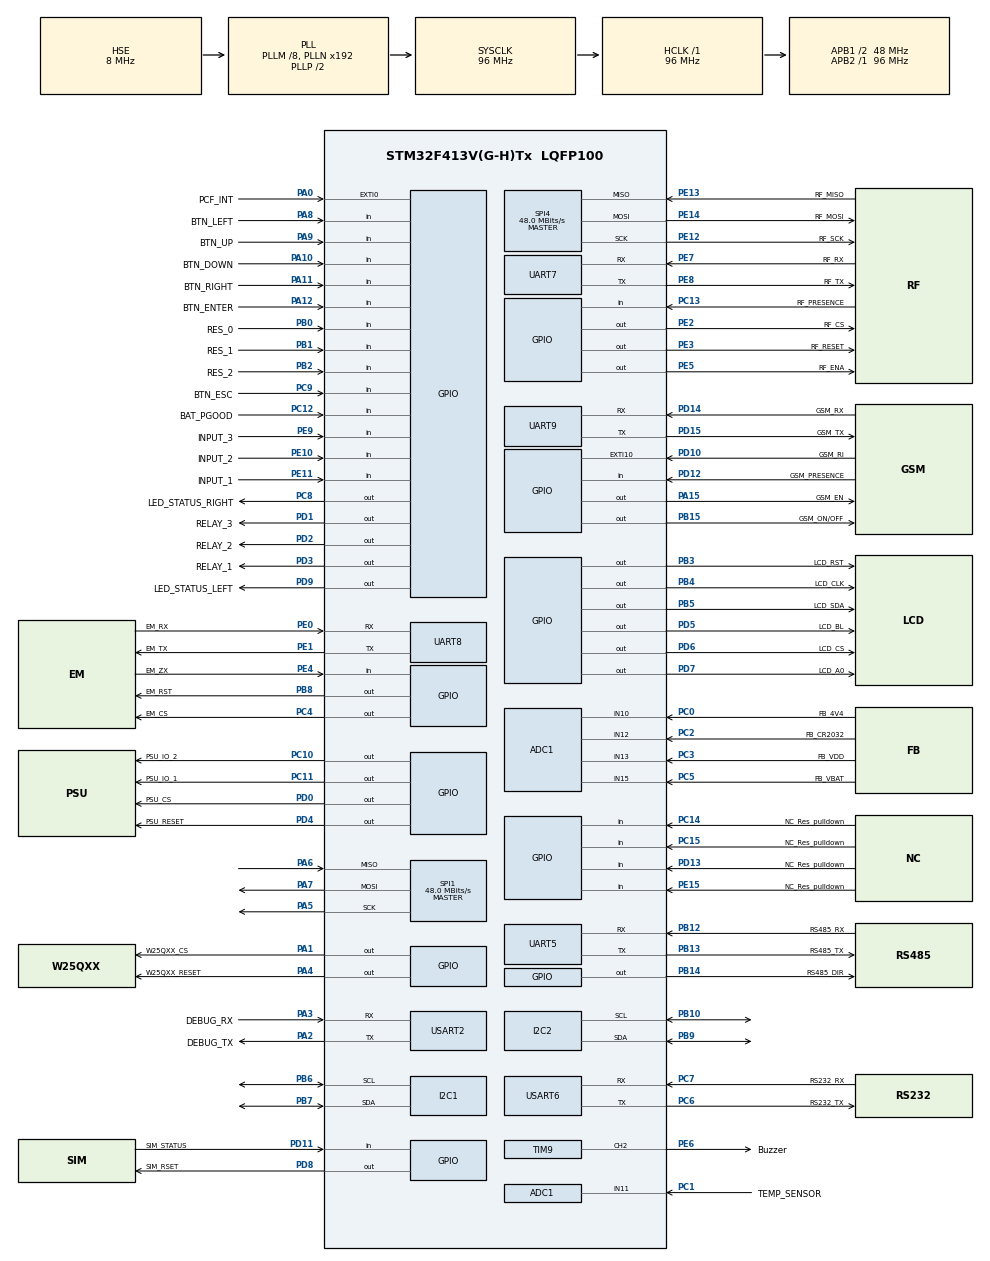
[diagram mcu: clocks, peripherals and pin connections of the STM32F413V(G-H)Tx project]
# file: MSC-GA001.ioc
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ADC1.Channel-0\#ChannelRegularConversion=ADC_CHANNEL_10
ADC1.NbrOfConversionFlag=1
ADC1.Rank-0\#ChannelRegularConversion=1
ADC1.SamplingTime-0\#ChannelRegularConversion=ADC_SAMPLETIME_3CYCLES
ADC1.master=1
Mcu.Family=STM32F4
Mcu.Name=STM32F413V(G-H)Tx
Mcu.Package=LQFP100
NVIC.PriorityGroup=NVIC_PRIORITYGROUP_4
NVIC.TIM1_BRK_TIM9_IRQn=true\:0\:0\:false\:false\:true\:true\:true
PA0.GPIO_Label=PCF_INT
PA0.GPIO_PuPd=GPIO_PULLUP
PA0.Signal=GPXTI0
PA1.GPIO_Label=W25QXX_CS
PA1.Signal=GPIO_Output
PA10.GPIO_Label=BTN_DOWN
PA10.GPIO_PuPd=GPIO_PULLUP
PA10.Signal=GPIO_Input
PA11.GPIO_Label=BTN_RIGHT
PA11.GPIO_PuPd=GPIO_PULLUP
PA11.Signal=GPIO_Input
PA12.GPIO_Label=BTN_ENTER
PA12.GPIO_PuPd=GPIO_PULLUP
PA12.Signal=GPIO_Input
PA13.Mode=Serial_Wire
PA13.Signal=SYS_JTMS-SWDIO
PA14.Mode=Serial_Wire
PA14.Signal=SYS_JTCK-SWCLK
PA15.GPIO_Label=GSM_EN
PA15.GPIO_PuPd=GPIO_PULLUP
PA15.Signal=GPIO_Output
PA2.GPIO_Label=DEBUG_TX
PA2.Mode=Asynchronous
PA2.Signal=USART2_TX
PA3.GPIO_Label=DEBUG_RX
PA3.Mode=Asynchronous
PA3.Signal=USART2_RX
PA4.GPIO_Label=W25QXX_RESET
PA4.Signal=GPIO_Output
PA5.Mode=Full_Duplex_Master
PA5.Signal=SPI1_SCK
PA6.Mode=Full_Duplex_Master
PA6.Signal=SPI1_MISO
PA7.Mode=Full_Duplex_Master
PA7.Signal=SPI1_MOSI
PA8.GPIO_Label=BTN_LEFT
PA8.GPIO_PuPd=GPIO_PULLUP
PA8.Signal=GPIO_Input
PA9.GPIO_Label=BTN_UP
PA9.GPIO_PuPd=GPIO_PULLUP
PA9.Signal=GPIO_Input
PB0.GPIO_Label=RES_0
PB0.GPIO_PuPd=GPIO_PULLUP
PB0.Signal=GPIO_Input
PB1.GPIO_Label=RES_1
PB1.GPIO_PuPd=GPIO_PULLUP
PB1.Signal=GPIO_Input
PB10.Mode=I2C
PB10.Signal=I2C2_SCL
PB12.GPIO_Label=RS485_RX
PB12.Mode=Asynchronous
PB12.Signal=UART5_RX
PB13.GPIO_Label=RS485_TX
PB13.Mode=Asynchronous
PB13.Signal=UART5_TX
PB14.GPIO_Label=RS485_DIR
PB14.Signal=GPIO_Output
PB15.GPIO_Label=GSM_ON/OFF
PB15.Signal=GPIO_Output
PB2.GPIO_Label=RES_2
PB2.GPIO_PuPd=GPIO_PULLUP
PB2.Signal=GPIO_Input
PB3.GPIO_Label=LCD_RST
PB3.Signal=GPIO_Output
PB4.GPIO_Label=LCD_CLK
PB4.Signal=GPIO_Output
PB5.GPIO_Label=LCD_SDA
PB5.Signal=GPIO_Output
PB6.Mode=I2C
PB6.Signal=I2C1_SCL
PB7.Mode=I2C
PB7.Signal=I2C1_SDA
PB8.GPIO_Label=EM_RST
PB8.Signal=GPIO_Output
PB9.Mode=I2C
PB9.Signal=I2C2_SDA
PC0.GPIO_Label=FB_4V4
PC0.Signal=ADCx_IN10
PC1.GPIO_Label=TEMP_SENSOR
PC1.Signal=ADCx_IN11
PC10.GPIO_Label=PSU_IO_2
PC10.Signal=GPIO_Output
PC11.GPIO_Label=PSU_IO_1
PC11.Signal=GPIO_Output
PC12.GPIO_Label=BAT_PGOOD
PC12.GPIO_PuPd=GPIO_PULLUP
PC12.Signal=GPIO_Input
PC13.GPIO_Label=RF_PRESENCE
PC13.GPIO_PuPd=GPIO_PULLUP
PC13.Signal=GPIO_Input
PC14-OSC32_IN.GPIO_Label=NC_Res_pulldown
PC14-OSC32_IN.GPIO_PuPd=GPIO_PULLDOWN
PC14-OSC32_IN.Signal=GPIO_Input
PC15-OSC32_OUT.GPIO_Label=NC_Res_pulldown
PC15-OSC32_OUT.GPIO_PuPd=GPIO_PULLDOWN
PC15-OSC32_OUT.Signal=GPIO_Input
PC2.GPIO_Label=FB_CR2032
PC2.Signal=ADCx_IN12
PC3.GPIO_Label=FB_VDD
PC3.Signal=ADCx_IN13
PC4.GPIO_Label=EM_CS
PC4.Signal=GPIO_Output
PC5.GPIO_Label=FB_VBAT
PC5.Signal=ADCx_IN15
PC6.GPIO_Label=RS232_TX
PC6.Mode=Asynchronous
PC6.Signal=USART6_TX
PC7.GPIO_Label=RS232_RX
PC7.Mode=Asynchronous
PC7.Signal=USART6_RX
PC8.GPIO_Label=LED_STATUS_RIGHT
PC8.Signal=GPIO_Output
PC9.GPIO_Label=BTN_ESC
PC9.GPIO_PuPd=GPIO_PULLUP
PC9.Signal=GPIO_Input
PD0.GPIO_Label=PSU_CS
PD0.Signal=GPIO_Output
PD1.GPIO_Label=RELAY_3
PD1.Signal=GPIO_Output
PD10.GPIO_Label=GSM_RI
PD10.GPIO_PuPd=GPIO_PULLUP
PD10.Signal=GPXTI10
PD11.GPIO_Label=SIM_STATUS
PD11.GPIO_PuPd=GPIO_PULLUP
PD11.Signal=GPIO_Input
PD12.GPIO_Label=GSM_PRESENCE
PD12.GPIO_PuPd=GPIO_PULLUP
PD12.Signal=GPIO_Input
PD13.GPIO_Label=NC_Res_pulldown
PD13.GPIO_PuPd=GPIO_PULLDOWN
PD13.Signal=GPIO_Input
PD14.GPIO_Label=GSM_RX
PD14.Mode=Asynchronous
PD14.Signal=UART9_RX
PD15.GPIO_Label=GSM_TX
PD15.Mode=Asynchronous
PD15.Signal=UART9_TX
PD2.GPIO_Label=RELAY_2
PD2.Signal=GPIO_Output
PD3.GPIO_Label=RELAY_1
PD3.Signal=GPIO_Output
PD4.GPIO_Label=PSU_RESET
PD4.Signal=GPIO_Output
PD5.GPIO_Label=LCD_BL
PD5.Signal=GPIO_Output
PD6.GPIO_Label=LCD_CS
PD6.Signal=GPIO_Output
PD7.GPIO_Label=LCD_A0
PD7.Signal=GPIO_Output
PD8.GPIO_Label=SIM_RSET
PD8.Signal=GPIO_Output
PD9.GPIO_Label=LED_STATUS_LEFT
PD9.Signal=GPIO_Output
PE0.GPIO_Label=EM_RX
PE0.Mode=Asynchronous
PE0.Signal=UART8_RX
PE1.GPIO_Label=EM_TX
PE1.Mode=Asynchronous
PE1.Signal=UART8_TX
PE10.GPIO_Label=INPUT_2
PE10.GPIO_PuPd=GPIO_PULLUP
PE10.Signal=GPIO_Input
PE11.GPIO_Label=INPUT_1
PE11.GPIO_PuPd=GPIO_PULLUP
PE11.Signal=GPIO_Input
PE12.GPIO_Label=RF_SCK
PE12.Mode=Full_Duplex_Master
PE12.Signal=SPI4_SCK
PE13.GPIO_Label=RF_MISO
PE13.Mode=Full_Duplex_Master
PE13.Signal=SPI4_MISO
PE14.GPIO_Label=RF_MOSI
PE14.Mode=Full_Duplex_Master
PE14.Signal=SPI4_MOSI
PE15.GPIO_Label=NC_Res_pulldown
PE15.GPIO_PuPd=GPIO_PULLDOWN
PE15.Signal=GPIO_Input
PE2.GPIO_Label=RF_CS
PE2.Signal=GPIO_Output
PE3.GPIO_Label=RF_RESET
PE3.Signal=GPIO_Output
PE4.GPIO_Label=EM_ZX
PE4.GPIO_PuPd=GPIO_PULLUP
PE4.Signal=GPIO_Input
PE5.GPIO_Label=RF_ENA
PE5.Signal=GPIO_Output
PE6.GPIO_Label=Buzzer
PE6.Signal=S_TIM9_CH2
PE7.GPIO_Label=RF_RX
PE7.Mode=Asynchronous
PE7.Signal=UART7_RX
PE8.GPIO_Label=RF_TX
PE8.Mode=Asynchronous
PE8.Signal=UART7_TX
PE9.GPIO_Label=INPUT_3
PE9.GPIO_PuPd=GPIO_PULLUP
PE9.Signal=GPIO_Input
PH0\ -\ OSC_IN.Mode=HSE-External-Oscillator
PH0\ -\ OSC_IN.Signal=RCC_OSC_IN
PH1\ -\ OSC_OUT.Mode=HSE-External-Oscillator
PH1\ -\ OSC_OUT.Signal=RCC_OSC_OUT
ProjectManager.HeapSize=0x200
ProjectManager.StackSize=0x400
ProjectManager.TargetToolchain=STM32CubeIDE
RCC.AHBFreq_Value=96000000
RCC.APB1CLKDivider=RCC_HCLK_DIV2
RCC.APB1Freq_Value=48000000
RCC.APB1TimFreq_Value=96000000
RCC.APB2Freq_Value=96000000
RCC.APB2TimFreq_Value=96000000
RCC.CortexFreq_Value=96000000
RCC.EnbaleCSS=true
RCC.HCLKFreq_Value=96000000
RCC.HSE_VALUE=8000000
RCC.PLLM=8
RCC.PLLSourceVirtual=RCC_PLLSOURCE_HSE
RCC.SYSCLKFreq_VALUE=96000000
RCC.SYSCLKSource=RCC_SYSCLKSOURCE_PLLCLK
RCC.USBFreq_Value=96000000
RCC.VCOOutputFreq_Value=192000000
SH.ADCx_IN10.0=ADC1_IN10,IN10
SH.ADCx_IN11.0=ADC1_IN11,IN11
SH.ADCx_IN12.0=ADC1_IN12,IN12
SH.ADCx_IN13.0=ADC1_IN13,IN13
SH.ADCx_IN15.0=ADC1_IN15,IN15
SH.S_TIM9_CH2.0=TIM9_CH2,PWM Generation2 CH2
SPI1.CalculateBaudRate=48.0 MBits/s
SPI1.Direction=SPI_DIRECTION_2LINES
SPI1.Mode=SPI_MODE_MASTER
SPI1.VirtualType=VM_MASTER
SPI4.CalculateBaudRate=48.0 MBits/s
SPI4.Direction=SPI_DIRECTION_2LINES
SPI4.Mode=SPI_MODE_MASTER
SPI4.VirtualType=VM_MASTER
TIM9.AutoReloadPreload=TIM_AUTORELOAD_PRELOAD_ENABLE
TIM9.Channel-PWM\ Generation2\ CH2=TIM_CHANNEL_2
TIM9.Period=1000-1
TIM9.Prescaler=24-1
TIM9.Pulse-PWM\ Generation2\ CH2=0
UART5.VirtualMode=Asynchronous
UART7.VirtualMode=Asynchronous
UART8.VirtualMode=Asynchronous
UART9.VirtualMode=Asynchronous
USART2.VirtualMode=VM_ASYNC
USART6.VirtualMode=VM_ASYNC
board=custom

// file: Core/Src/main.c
/* USER CODE BEGIN Header */
/**
  ******************************************************************************
  * @file           : main.c
  * @brief          : Main program body
  ******************************************************************************
  * @attention
  *
  * <h2><center>&copy; Copyright (c) 2021 STMicroelectronics.
  * All rights reserved.</center></h2>
  *
  * This software component is licensed by ST under BSD 3-Clause license,
  * the "License"; You may not use this file except in compliance with the
  * License. You may obtain a copy of the License at:
  *                        opensource.org/licenses/BSD-3-Clause
  *
  ******************************************************************************
  */
/* USER CODE END Header */
#include "main.h"

/* USER CODE BEGIN Includes */
#include "../apps/resource.h"
/* USER CODE END Includes */

ADC_HandleTypeDef hadc1;

I2C_HandleTypeDef hi2c1;
I2C_HandleTypeDef hi2c2;

SPI_HandleTypeDef hspi1;
SPI_HandleTypeDef hspi4;

TIM_HandleTypeDef htim9;

UART_HandleTypeDef huart5;
UART_HandleTypeDef huart7;
UART_HandleTypeDef huart8;
UART_HandleTypeDef huart9;
UART_HandleTypeDef huart2;
UART_HandleTypeDef huart6;

void SystemClock_Config(void);
static void MX_GPIO_Init(void);
static void MX_ADC1_Init(void);
static void MX_I2C1_Init(void);
static void MX_I2C2_Init(void);
static void MX_SPI1_Init(void);
static void MX_SPI4_Init(void);
static void MX_UART5_Init(void);
static void MX_UART7_Init(void);
static void MX_UART8_Init(void);
static void MX_UART9_Init(void);
static void MX_USART2_UART_Init(void);
static void MX_USART6_UART_Init(void);
static void MX_TIM9_Init(void);

int main(void)
{

  /* MCU Configuration--------------------------------------------------------*/

  /* Reset of all peripherals, Initializes the Flash interface and the Systick. */
  HAL_Init();

  /* Configure the system clock */
  SystemClock_Config();

  /* Initialize all configured peripherals */
  MX_GPIO_Init();
  MX_ADC1_Init();
  MX_I2C1_Init();
  MX_I2C2_Init();
  MX_SPI1_Init();
  MX_SPI4_Init();
  MX_UART5_Init();
  MX_UART7_Init();
  MX_UART8_Init();
  MX_UART9_Init();
  MX_USART2_UART_Init();
  MX_USART6_UART_Init();
  MX_TIM9_Init();
  /* USER CODE BEGIN 2 */
  /*start timer 9 for PWM out for the buzzer*/
  HAL_TIM_Base_Start_IT(&htim9);
  /* Enable the main output */
  HAL_TIM_PWM_Start(&htim9, TIM_CHANNEL_2);//Buzzer
  /*Update the duty cycle based on the period setting from QMX ==>1000 is 4kHz frequency,
   and 50% duty cycle*/
  htim9.Init.Period = 1000-1;
  htim9.Instance->CCR1 = (unsigned short) ((uint32_t) (Duty_Percent*htim9.Init.Period/100));

  /* USER CODE END 2 */

  /* Infinite loop */
  /* USER CODE BEGIN WHILE */
  while (1)
  {
	  //update all timers
	  DoTimers();
	  //update all switches
	  UpdateAllSwitches();
	  /*Update all the LED data from the buffer*/
	  UpdateLEDoutputs(&RawLEDdata);
	  //Toggle LED to test the loop continuing
	  ToggleLEDstate(&RawLEDdata,LED_STATUS_RIGHT);
	  //Run main app
	  doApplication();
	  //LCD display driver
	  doDisplay();
	  /*Buzzer driver*/
	  doBeepControl();
	  /*Update the buzzer out put*/
	  DoPWM_Buzzer(htim9, Duty_Percent);
    /* USER CODE END WHILE */

  }
}

void SystemClock_Config(void)
{
  RCC_OscInitTypeDef RCC_OscInitStruct = {0};
  RCC_ClkInitTypeDef RCC_ClkInitStruct = {0};

  /** Configure the main internal regulator output voltage
  */
  __HAL_RCC_PWR_CLK_ENABLE();
  __HAL_PWR_VOLTAGESCALING_CONFIG(PWR_REGULATOR_VOLTAGE_SCALE1);
  /** Initializes the RCC Oscillators according to the specified parameters
  * in the RCC_OscInitTypeDef structure.
  */
  RCC_OscInitStruct.OscillatorType = RCC_OSCILLATORTYPE_HSE;
  RCC_OscInitStruct.HSEState = RCC_HSE_ON;
  RCC_OscInitStruct.PLL.PLLState = RCC_PLL_ON;
  RCC_OscInitStruct.PLL.PLLSource = RCC_PLLSOURCE_HSE;
  RCC_OscInitStruct.PLL.PLLM = 8;
  RCC_OscInitStruct.PLL.PLLN = 192;
  RCC_OscInitStruct.PLL.PLLP = RCC_PLLP_DIV2;
  RCC_OscInitStruct.PLL.PLLQ = 2;
  RCC_OscInitStruct.PLL.PLLR = 2;
  if (HAL_RCC_OscConfig(&RCC_OscInitStruct) != HAL_OK)
  {
    Error_Handler();
  }
  /** Initializes the CPU, AHB and APB buses clocks
  */
  RCC_ClkInitStruct.ClockType = RCC_CLOCKTYPE_HCLK|RCC_CLOCKTYPE_SYSCLK
                              |RCC_CLOCKTYPE_PCLK1|RCC_CLOCKTYPE_PCLK2;
  RCC_ClkInitStruct.SYSCLKSource = RCC_SYSCLKSOURCE_PLLCLK;
  RCC_ClkInitStruct.AHBCLKDivider = RCC_SYSCLK_DIV1;
  RCC_ClkInitStruct.APB1CLKDivider = RCC_HCLK_DIV2;
  RCC_ClkInitStruct.APB2CLKDivider = RCC_HCLK_DIV1;

  if (HAL_RCC_ClockConfig(&RCC_ClkInitStruct, FLASH_LATENCY_3) != HAL_OK)
  {
    Error_Handler();
  }
  /** Enables the Clock Security System
  */
  HAL_RCC_EnableCSS();
}

static void MX_ADC1_Init(void)
{

  ADC_ChannelConfTypeDef sConfig = {0};

  /** Configure the global features of the ADC (Clock, Resolution, Data Alignment and number of conversion)
  */
  hadc1.Instance = ADC1;
  hadc1.Init.ClockPrescaler = ADC_CLOCK_SYNC_PCLK_DIV4;
  hadc1.Init.Resolution = ADC_RESOLUTION_12B;
  hadc1.Init.ScanConvMode = DISABLE;
  hadc1.Init.ContinuousConvMode = DISABLE;
  hadc1.Init.DiscontinuousConvMode = DISABLE;
  hadc1.Init.ExternalTrigConvEdge = ADC_EXTERNALTRIGCONVEDGE_NONE;
  hadc1.Init.ExternalTrigConv = ADC_SOFTWARE_START;
  hadc1.Init.DataAlign = ADC_DATAALIGN_RIGHT;
  hadc1.Init.NbrOfConversion = 1;
  hadc1.Init.DMAContinuousRequests = DISABLE;
  hadc1.Init.EOCSelection = ADC_EOC_SINGLE_CONV;
  if (HAL_ADC_Init(&hadc1) != HAL_OK)
  {
    Error_Handler();
  }
  /** Configure for the selected ADC regular channel its corresponding rank in the sequencer and its sample time.
  */
  sConfig.Channel = ADC_CHANNEL_10;
  sConfig.Rank = 1;
  sConfig.SamplingTime = ADC_SAMPLETIME_3CYCLES;
  if (HAL_ADC_ConfigChannel(&hadc1, &sConfig) != HAL_OK)
  {
    Error_Handler();
  }

}

static void MX_I2C1_Init(void)
{

  hi2c1.Instance = I2C1;
  hi2c1.Init.ClockSpeed = 100000;
  hi2c1.Init.DutyCycle = I2C_DUTYCYCLE_2;
  hi2c1.Init.OwnAddress1 = 0;
  hi2c1.Init.AddressingMode = I2C_ADDRESSINGMODE_7BIT;
  hi2c1.Init.DualAddressMode = I2C_DUALADDRESS_DISABLE;
  hi2c1.Init.OwnAddress2 = 0;
  hi2c1.Init.GeneralCallMode = I2C_GENERALCALL_DISABLE;
  hi2c1.Init.NoStretchMode = I2C_NOSTRETCH_DISABLE;
  if (HAL_I2C_Init(&hi2c1) != HAL_OK)
  {
    Error_Handler();
  }

}

static void MX_I2C2_Init(void)
{

  hi2c2.Instance = I2C2;
  hi2c2.Init.ClockSpeed = 100000;
  hi2c2.Init.DutyCycle = I2C_DUTYCYCLE_2;
  hi2c2.Init.OwnAddress1 = 0;
  hi2c2.Init.AddressingMode = I2C_ADDRESSINGMODE_7BIT;
  hi2c2.Init.DualAddressMode = I2C_DUALADDRESS_DISABLE;
  hi2c2.Init.OwnAddress2 = 0;
  hi2c2.Init.GeneralCallMode = I2C_GENERALCALL_DISABLE;
  hi2c2.Init.NoStretchMode = I2C_NOSTRETCH_DISABLE;
  if (HAL_I2C_Init(&hi2c2) != HAL_OK)
  {
    Error_Handler();
  }

}

static void MX_SPI1_Init(void)
{

  /* SPI1 parameter configuration*/
  hspi1.Instance = SPI1;
  hspi1.Init.Mode = SPI_MODE_MASTER;
  hspi1.Init.Direction = SPI_DIRECTION_2LINES;
  hspi1.Init.DataSize = SPI_DATASIZE_8BIT;
  hspi1.Init.CLKPolarity = SPI_POLARITY_LOW;
  hspi1.Init.CLKPhase = SPI_PHASE_1EDGE;
  hspi1.Init.NSS = SPI_NSS_SOFT;
  hspi1.Init.BaudRatePrescaler = SPI_BAUDRATEPRESCALER_2;
  hspi1.Init.FirstBit = SPI_FIRSTBIT_MSB;
  hspi1.Init.TIMode = SPI_TIMODE_DISABLE;
  hspi1.Init.CRCCalculation = SPI_CRCCALCULATION_DISABLE;
  hspi1.Init.CRCPolynomial = 10;
  if (HAL_SPI_Init(&hspi1) != HAL_OK)
  {
    Error_Handler();
  }

}

static void MX_SPI4_Init(void)
{

  /* SPI4 parameter configuration*/
  hspi4.Instance = SPI4;
  hspi4.Init.Mode = SPI_MODE_MASTER;
  hspi4.Init.Direction = SPI_DIRECTION_2LINES;
  hspi4.Init.DataSize = SPI_DATASIZE_8BIT;
  hspi4.Init.CLKPolarity = SPI_POLARITY_LOW;
  hspi4.Init.CLKPhase = SPI_PHASE_1EDGE;
  hspi4.Init.NSS = SPI_NSS_SOFT;
  hspi4.Init.BaudRatePrescaler = SPI_BAUDRATEPRESCALER_2;
  hspi4.Init.FirstBit = SPI_FIRSTBIT_MSB;
  hspi4.Init.TIMode = SPI_TIMODE_DISABLE;
  hspi4.Init.CRCCalculation = SPI_CRCCALCULATION_DISABLE;
  hspi4.Init.CRCPolynomial = 10;
  if (HAL_SPI_Init(&hspi4) != HAL_OK)
  {
    Error_Handler();
  }

}

static void MX_TIM9_Init(void)
{

  TIM_OC_InitTypeDef sConfigOC = {0};

  htim9.Instance = TIM9;
  htim9.Init.Prescaler = 24-1;
  htim9.Init.CounterMode = TIM_COUNTERMODE_UP;
  htim9.Init.Period = 1000-1;
  htim9.Init.ClockDivision = TIM_CLOCKDIVISION_DIV1;
  htim9.Init.AutoReloadPreload = TIM_AUTORELOAD_PRELOAD_ENABLE;
  if (HAL_TIM_PWM_Init(&htim9) != HAL_OK)
  {
    Error_Handler();
  }
  sConfigOC.OCMode = TIM_OCMODE_PWM1;
  sConfigOC.Pulse = 0;
  sConfigOC.OCPolarity = TIM_OCPOLARITY_HIGH;
  sConfigOC.OCFastMode = TIM_OCFAST_DISABLE;
  if (HAL_TIM_PWM_ConfigChannel(&htim9, &sConfigOC, TIM_CHANNEL_2) != HAL_OK)
  {
    Error_Handler();
  }
  HAL_TIM_MspPostInit(&htim9);

}

static void MX_UART5_Init(void)
{

  huart5.Instance = UART5;
  huart5.Init.BaudRate = 115200;
  huart5.Init.WordLength = UART_WORDLENGTH_8B;
  huart5.Init.StopBits = UART_STOPBITS_1;
  huart5.Init.Parity = UART_PARITY_NONE;
  huart5.Init.Mode = UART_MODE_TX_RX;
  huart5.Init.HwFlowCtl = UART_HWCONTROL_NONE;
  huart5.Init.OverSampling = UART_OVERSAMPLING_16;
  if (HAL_UART_Init(&huart5) != HAL_OK)
  {
    Error_Handler();
  }

}

static void MX_UART7_Init(void)
{

  huart7.Instance = UART7;
  huart7.Init.BaudRate = 115200;
  huart7.Init.WordLength = UART_WORDLENGTH_8B;
  huart7.Init.StopBits = UART_STOPBITS_1;
  huart7.Init.Parity = UART_PARITY_NONE;
  huart7.Init.Mode = UART_MODE_TX_RX;
  huart7.Init.HwFlowCtl = UART_HWCONTROL_NONE;
  huart7.Init.OverSampling = UART_OVERSAMPLING_16;
  if (HAL_UART_Init(&huart7) != HAL_OK)
  {
    Error_Handler();
  }

}

static void MX_UART8_Init(void)
{

  huart8.Instance = UART8;
  huart8.Init.BaudRate = 115200;
  huart8.Init.WordLength = UART_WORDLENGTH_8B;
  huart8.Init.StopBits = UART_STOPBITS_1;
  huart8.Init.Parity = UART_PARITY_NONE;
  huart8.Init.Mode = UART_MODE_TX_RX;
  huart8.Init.HwFlowCtl = UART_HWCONTROL_NONE;
  huart8.Init.OverSampling = UART_OVERSAMPLING_16;
  if (HAL_UART_Init(&huart8) != HAL_OK)
  {
    Error_Handler();
  }

}

static void MX_UART9_Init(void)
{

  huart9.Instance = UART9;
  huart9.Init.BaudRate = 115200;
  huart9.Init.WordLength = UART_WORDLENGTH_8B;
  huart9.Init.StopBits = UART_STOPBITS_1;
  huart9.Init.Parity = UART_PARITY_NONE;
  huart9.Init.Mode = UART_MODE_TX_RX;
  huart9.Init.HwFlowCtl = UART_HWCONTROL_NONE;
  huart9.Init.OverSampling = UART_OVERSAMPLING_16;
  if (HAL_UART_Init(&huart9) != HAL_OK)
  {
    Error_Handler();
  }

}

static void MX_USART2_UART_Init(void)
{

  huart2.Instance = USART2;
  huart2.Init.BaudRate = 115200;
  huart2.Init.WordLength = UART_WORDLENGTH_8B;
  huart2.Init.StopBits = UART_STOPBITS_1;
  huart2.Init.Parity = UART_PARITY_NONE;
  huart2.Init.Mode = UART_MODE_TX_RX;
  huart2.Init.HwFlowCtl = UART_HWCONTROL_NONE;
  huart2.Init.OverSampling = UART_OVERSAMPLING_16;
  if (HAL_UART_Init(&huart2) != HAL_OK)
  {
    Error_Handler();
  }

}

static void MX_USART6_UART_Init(void)
{

  huart6.Instance = USART6;
  huart6.Init.BaudRate = 115200;
  huart6.Init.WordLength = UART_WORDLENGTH_8B;
  huart6.Init.StopBits = UART_STOPBITS_1;
  huart6.Init.Parity = UART_PARITY_NONE;
  huart6.Init.Mode = UART_MODE_TX_RX;
  huart6.Init.HwFlowCtl = UART_HWCONTROL_NONE;
  huart6.Init.OverSampling = UART_OVERSAMPLING_16;
  if (HAL_UART_Init(&huart6) != HAL_OK)
  {
    Error_Handler();
  }

}

static void MX_GPIO_Init(void)
{
  GPIO_InitTypeDef GPIO_InitStruct = {0};

  /* GPIO Ports Clock Enable */
  __HAL_RCC_GPIOE_CLK_ENABLE();
  __HAL_RCC_GPIOC_CLK_ENABLE();
  __HAL_RCC_GPIOH_CLK_ENABLE();
  __HAL_RCC_GPIOA_CLK_ENABLE();
  __HAL_RCC_GPIOB_CLK_ENABLE();
  __HAL_RCC_GPIOD_CLK_ENABLE();

  /*Configure GPIO pin Output Level */
  HAL_GPIO_WritePin(GPIOE, RF_CS_Pin|RF_RESET_Pin|RF_ENA_Pin, GPIO_PIN_RESET);

  /*Configure GPIO pin Output Level */
  HAL_GPIO_WritePin(GPIOA, W25QXX_CS_Pin|W25QXX_RESET_Pin|GSM_EN_Pin, GPIO_PIN_RESET);

  /*Configure GPIO pin Output Level */
  HAL_GPIO_WritePin(GPIOC, EM_CS_Pin|LED_STATUS_RIGHT_Pin|PSU_IO_2_Pin|PSU_IO_1_Pin, GPIO_PIN_RESET);

  /*Configure GPIO pin Output Level */
  HAL_GPIO_WritePin(GPIOB, RS485_DIR_Pin|GSM_ON_OFF_Pin|LCD_RST_Pin|LCD_CLK_Pin
                          |LCD_SDA_Pin|EM_RST_Pin, GPIO_PIN_RESET);

  /*Configure GPIO pin Output Level */
  HAL_GPIO_WritePin(GPIOD, SIM_RSET_Pin|LED_STATUS_LEFT_Pin|PSU_CS_Pin|RELAY_3_Pin
                          |RELAY_2_Pin|RELAY_1_Pin|PSU_RESET_Pin|LCD_BL_Pin
                          |LCD_CS_Pin|LCD_A0_Pin, GPIO_PIN_RESET);

  /*Configure GPIO pins : RF_CS_Pin RF_RESET_Pin RF_ENA_Pin */
  GPIO_InitStruct.Pin = RF_CS_Pin|RF_RESET_Pin|RF_ENA_Pin;
  GPIO_InitStruct.Mode = GPIO_MODE_OUTPUT_PP;
  GPIO_InitStruct.Pull = GPIO_NOPULL;
  GPIO_InitStruct.Speed = GPIO_SPEED_FREQ_LOW;
  HAL_GPIO_Init(GPIOE, &GPIO_InitStruct);

  /*Configure GPIO pins : EM_ZX_Pin INPUT_3_Pin INPUT_2_Pin INPUT_1_Pin */
  GPIO_InitStruct.Pin = EM_ZX_Pin|INPUT_3_Pin|INPUT_2_Pin|INPUT_1_Pin;
  GPIO_InitStruct.Mode = GPIO_MODE_INPUT;
  GPIO_InitStruct.Pull = GPIO_PULLUP;
  HAL_GPIO_Init(GPIOE, &GPIO_InitStruct);

  /*Configure GPIO pins : RF_PRESENCE_Pin BTN_ESC_Pin BAT_PGOOD_Pin */
  GPIO_InitStruct.Pin = RF_PRESENCE_Pin|BTN_ESC_Pin|BAT_PGOOD_Pin;
  GPIO_InitStruct.Mode = GPIO_MODE_INPUT;
  GPIO_InitStruct.Pull = GPIO_PULLUP;
  HAL_GPIO_Init(GPIOC, &GPIO_InitStruct);

  /*Configure GPIO pins : NC_Res_pulldown_Pin NC_Res_pulldownC15_Pin */
  GPIO_InitStruct.Pin = NC_Res_pulldown_Pin|NC_Res_pulldownC15_Pin;
  GPIO_InitStruct.Mode = GPIO_MODE_INPUT;
  GPIO_InitStruct.Pull = GPIO_PULLDOWN;
  HAL_GPIO_Init(GPIOC, &GPIO_InitStruct);

  /*Configure GPIO pin : PCF_INT_Pin */
  GPIO_InitStruct.Pin = PCF_INT_Pin;
  GPIO_InitStruct.Mode = GPIO_MODE_IT_RISING;
  GPIO_InitStruct.Pull = GPIO_PULLUP;
  HAL_GPIO_Init(PCF_INT_GPIO_Port, &GPIO_InitStruct);

  /*Configure GPIO pins : W25QXX_CS_Pin W25QXX_RESET_Pin */
  GPIO_InitStruct.Pin = W25QXX_CS_Pin|W25QXX_RESET_Pin;
  GPIO_InitStruct.Mode = GPIO_MODE_OUTPUT_PP;
  GPIO_InitStruct.Pull = GPIO_NOPULL;
  GPIO_InitStruct.Speed = GPIO_SPEED_FREQ_LOW;
  HAL_GPIO_Init(GPIOA, &GPIO_InitStruct);

  /*Configure GPIO pins : EM_CS_Pin LED_STATUS_RIGHT_Pin PSU_IO_2_Pin PSU_IO_1_Pin */
  GPIO_InitStruct.Pin = EM_CS_Pin|LED_STATUS_RIGHT_Pin|PSU_IO_2_Pin|PSU_IO_1_Pin;
  GPIO_InitStruct.Mode = GPIO_MODE_OUTPUT_PP;
  GPIO_InitStruct.Pull = GPIO_NOPULL;
  GPIO_InitStruct.Speed = GPIO_SPEED_FREQ_LOW;
  HAL_GPIO_Init(GPIOC, &GPIO_InitStruct);

  /*Configure GPIO pins : RES_0_Pin RES_1_Pin RES_2_Pin */
  GPIO_InitStruct.Pin = RES_0_Pin|RES_1_Pin|RES_2_Pin;
  GPIO_InitStruct.Mode = GPIO_MODE_INPUT;
  GPIO_InitStruct.Pull = GPIO_PULLUP;
  HAL_GPIO_Init(GPIOB, &GPIO_InitStruct);

  /*Configure GPIO pin : NC_Res_pulldownE15_Pin */
  GPIO_InitStruct.Pin = NC_Res_pulldownE15_Pin;
  GPIO_InitStruct.Mode = GPIO_MODE_INPUT;
  GPIO_InitStruct.Pull = GPIO_PULLDOWN;
  HAL_GPIO_Init(NC_Res_pulldownE15_GPIO_Port, &GPIO_InitStruct);

  /*Configure GPIO pins : RS485_DIR_Pin GSM_ON_OFF_Pin LCD_RST_Pin LCD_CLK_Pin
                           LCD_SDA_Pin EM_RST_Pin */
  GPIO_InitStruct.Pin = RS485_DIR_Pin|GSM_ON_OFF_Pin|LCD_RST_Pin|LCD_CLK_Pin
                          |LCD_SDA_Pin|EM_RST_Pin;
  GPIO_InitStruct.Mode = GPIO_MODE_OUTPUT_PP;
  GPIO_InitStruct.Pull = GPIO_NOPULL;
  GPIO_InitStruct.Speed = GPIO_SPEED_FREQ_LOW;
  HAL_GPIO_Init(GPIOB, &GPIO_InitStruct);

  /*Configure GPIO pins : SIM_RSET_Pin LED_STATUS_LEFT_Pin PSU_CS_Pin RELAY_3_Pin
                           RELAY_2_Pin RELAY_1_Pin PSU_RESET_Pin LCD_BL_Pin
                           LCD_CS_Pin LCD_A0_Pin */
  GPIO_InitStruct.Pin = SIM_RSET_Pin|LED_STATUS_LEFT_Pin|PSU_CS_Pin|RELAY_3_Pin
                          |RELAY_2_Pin|RELAY_1_Pin|PSU_RESET_Pin|LCD_BL_Pin
                          |LCD_CS_Pin|LCD_A0_Pin;
  GPIO_InitStruct.Mode = GPIO_MODE_OUTPUT_PP;
  GPIO_InitStruct.Pull = GPIO_NOPULL;
  GPIO_InitStruct.Speed = GPIO_SPEED_FREQ_LOW;
  HAL_GPIO_Init(GPIOD, &GPIO_InitStruct);

  /*Configure GPIO pin : GSM_RI_Pin */
  GPIO_InitStruct.Pin = GSM_RI_Pin;
  GPIO_InitStruct.Mode = GPIO_MODE_IT_RISING;
  GPIO_InitStruct.Pull = GPIO_PULLUP;
  HAL_GPIO_Init(GSM_RI_GPIO_Port, &GPIO_InitStruct);

  /*Configure GPIO pins : SIM_STATUS_Pin GSM_PRESENCE_Pin */
  GPIO_InitStruct.Pin = SIM_STATUS_Pin|GSM_PRESENCE_Pin;
  GPIO_InitStruct.Mode = GPIO_MODE_INPUT;
  GPIO_InitStruct.Pull = GPIO_PULLUP;
  HAL_GPIO_Init(GPIOD, &GPIO_InitStruct);

  /*Configure GPIO pin : NC_Res_pulldownD13_Pin */
  GPIO_InitStruct.Pin = NC_Res_pulldownD13_Pin;
  GPIO_InitStruct.Mode = GPIO_MODE_INPUT;
  GPIO_InitStruct.Pull = GPIO_PULLDOWN;
  HAL_GPIO_Init(NC_Res_pulldownD13_GPIO_Port, &GPIO_InitStruct);

  /*Configure GPIO pins : BTN_LEFT_Pin BTN_UP_Pin BTN_DOWN_Pin BTN_RIGHT_Pin
                           BTN_ENTER_Pin */
  GPIO_InitStruct.Pin = BTN_LEFT_Pin|BTN_UP_Pin|BTN_DOWN_Pin|BTN_RIGHT_Pin
                          |BTN_ENTER_Pin;
  GPIO_InitStruct.Mode = GPIO_MODE_INPUT;
  GPIO_InitStruct.Pull = GPIO_PULLUP;
  HAL_GPIO_Init(GPIOA, &GPIO_InitStruct);

  /*Configure GPIO pin : GSM_EN_Pin */
  GPIO_InitStruct.Pin = GSM_EN_Pin;
  GPIO_InitStruct.Mode = GPIO_MODE_OUTPUT_PP;
  GPIO_InitStruct.Pull = GPIO_PULLUP;
  GPIO_InitStruct.Speed = GPIO_SPEED_FREQ_LOW;
  HAL_GPIO_Init(GSM_EN_GPIO_Port, &GPIO_InitStruct);

}

void Error_Handler(void)
{
  __disable_irq();
  while (1)
  {
  }
}

/************************ (C) COPYRIGHT STMicroelectronics *****END OF FILE****/
